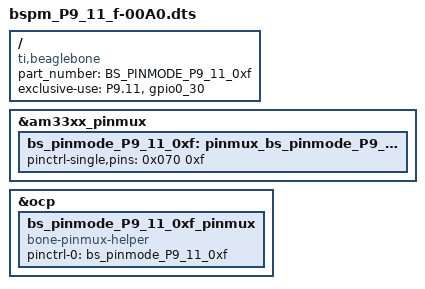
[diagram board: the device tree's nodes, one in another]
/*
 * This is a template-generated file from BoneScript
 */

/dts-v1/;
/plugin/;

/{
    compatible = "ti,beaglebone", "ti,beaglebone-black";
    part_number = "BS_PINMODE_P9_11_0xf";

    exclusive-use =
        "P9.11",
        "gpio0_30";

    fragment@0 {
        target = <&am33xx_pinmux>;
        __overlay__ {
            bs_pinmode_P9_11_0xf: pinmux_bs_pinmode_P9_11_0xf {
                pinctrl-single,pins = <0x070 0xf>;
            };
        };
    };

    fragment@1 {
        target = <&ocp>;
        __overlay__ {
            bs_pinmode_P9_11_0xf_pinmux {
                compatible = "bone-pinmux-helper";
                status = "okay";
                pinctrl-names = "default";
                pinctrl-0 = <&bs_pinmode_P9_11_0xf>;
            };
        };
    };
};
